# ATmega324PB device description
Architecture: AVR8; Family: megaAVR
Registers are 8-bit, access not given, no defined reset value unless marked. A register's access mark holds for its fields unless they carry their own. Offsets are from the block's base; [hi:lo] are bit positions.

## EEPROM
Instances: EEPROM 0x00
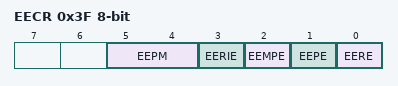
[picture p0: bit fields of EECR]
0x3F EECR — EEPROM Control Register
  [5:4] EEPM — EEPROM Programming Mode Bits
    0=Erase and Write in one operation; 1=Erase Only; 2=Write Only
  [3] EERIE — EEPROM Ready Interrupt Enable
  [2] EEMPE — EEPROM Master Programming Enable
  [1] EEPE — EEPROM Programming Enable
  [0] EERE — EEPROM Read Enable
0x40 EEDR — EEPROM Data Register
0x41 EEAR 16-bit bits used 11:0 — EEPROM Address Register Low Bytes

## SPI0 — Serial Peripheral Interface
Instances: SPI0 0x00
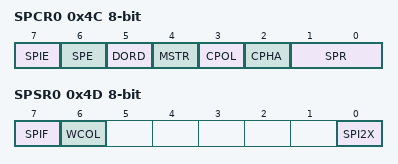
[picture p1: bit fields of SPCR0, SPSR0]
0x4C SPCR0 — SPI Control Register
  [7] SPIE — SPI Interrupt Enable
  [6] SPE — SPI Enable
  [5] DORD — Data Order
  [4] MSTR — Master/Slave Select
  [3] CPOL — Clock polarity
  [2] CPHA — Clock Phase
  [1:0] SPR — SPI Clock Rate Select
    0=fosc/4; 1=fosc/16; 2=fosc/64; 3=fosc/128; 4=fosc/2; 5=fosc/8; 6=fosc/32; 7=fosc/64
0x4D SPSR0 — SPI Status Register
  [7] SPIF — SPI Interrupt Flag
  [6] WCOL — Write Collision Flag
  [0] SPI2X — Double SPI Speed Bit
0x4E SPDR0 — SPI Data Register

## SPI1 — Serial Peripheral Interface
Instances: SPI1 0x00
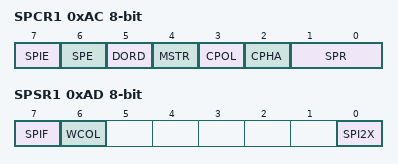
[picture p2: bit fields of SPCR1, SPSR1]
0xAC SPCR1 — SPI Control Register
  [7] SPIE — SPI Interrupt Enable
  [6] SPE — SPI Enable
  [5] DORD — Data Order
  [4] MSTR — Master/Slave Select
  [3] CPOL — Clock polarity
  [2] CPHA — Clock Phase
  [1:0] SPR — SPI Clock Rate Select
    0=fosc/4; 1=fosc/16; 2=fosc/64; 3=fosc/128; 4=fosc/2; 5=fosc/8; 6=fosc/32; 7=fosc/64
0xAD SPSR1 — SPI Status Register
  [7] SPIF — SPI Interrupt Flag
  [6] WCOL — Write Collision Flag
  [0] SPI2X — Double SPI Speed Bit
0xAE SPDR1 — SPI Data Register

## TWI0 — Two Wire Serial Interface
Instances: TWI0 0x00
0xB8 TWBR0 — TWI Bit Rate register
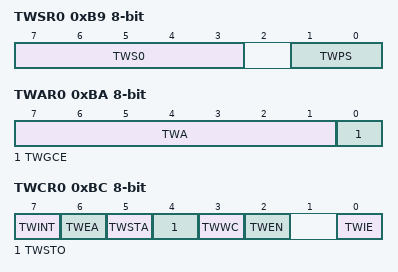
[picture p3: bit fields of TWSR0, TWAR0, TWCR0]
0xB9 TWSR0 — TWI Status Register
  [7:3] TWS0 (bit 3 of the value upward) — TWI Status
  [1:0] TWPS — TWI Prescaler
    0=1; 1=4; 2=16; 3=64
0xBA TWAR0 — TWI (Slave) Address register
  [7:1] TWA — TWI (Slave) Address register Bits
  [0] TWGCE — TWI General Call Recognition Enable Bit
0xBB TWDR0 — TWI Data register
0xBC TWCR0 — TWI Control Register
  [7] TWINT — TWI Interrupt Flag
  [6] TWEA — TWI Enable Acknowledge Bit
  [5] TWSTA — TWI Start Condition Bit
  [4] TWSTO — TWI Stop Condition Bit
  [3] TWWC — TWI Write Collition Flag
  [2] TWEN — TWI Enable Bit
  [0] TWIE — TWI Interrupt Enable
0xBD TWAMR0 — TWI (Slave) Address Mask Register
  [7:1] TWAM0

## TWI1 — Two Wire Serial Interface
Instances: TWI1 0x00
0xD8 TWBR1 — TWI Bit Rate register
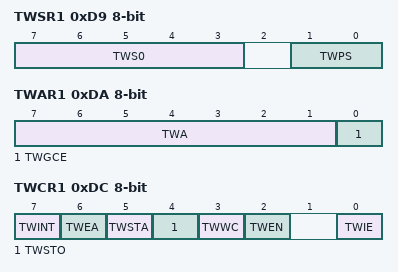
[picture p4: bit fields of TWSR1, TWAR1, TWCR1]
0xD9 TWSR1 — TWI Status Register
  [7:3] TWS0 (bit 3 of the value upward) — TWI Status
  [1:0] TWPS — TWI Prescaler
    0=1; 1=4; 2=16; 3=64
0xDA TWAR1 — TWI (Slave) Address register
  [7:1] TWA — TWI (Slave) Address register Bits
  [0] TWGCE — TWI General Call Recognition Enable Bit
0xDB TWDR1 — TWI Data register
0xDC TWCR1 — TWI Control Register
  [7] TWINT — TWI Interrupt Flag
  [6] TWEA — TWI Enable Acknowledge Bit
  [5] TWSTA — TWI Start Condition Bit
  [4] TWSTO — TWI Stop Condition Bit
  [3] TWWC — TWI Write Collition Flag
  [2] TWEN — TWI Enable Bit
  [0] TWIE — TWI Interrupt Enable
0xDD TWAMR1 — TWI (Slave) Address Mask Register
  [7:1] TWAM1

## CFD — Clock Failure Detection
Instances: CFD 0x00
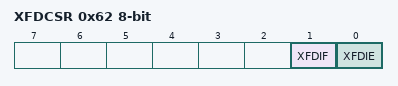
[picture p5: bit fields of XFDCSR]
0x62 XFDCSR — XOSC Failure Detection Control and Status Register
  [1] XFDIF — Failure Detection Interrupt Flag
  [0] XFDIE — Failure Detection Interrupt Enable

## CPU — CPU Registers
Instances: CPU 0x00
Parameters: CORE_VERSION=V2E
0x3E GPIOR0 — General Purpose IO Register 0
0x4A GPIOR1 — General Purpose IO Register 1
0x4B GPIOR2 — General Purpose IO Register 2
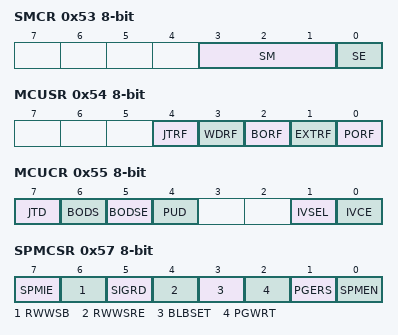
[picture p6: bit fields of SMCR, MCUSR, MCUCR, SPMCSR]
0x53 SMCR — Sleep Mode Control Register
  [3:1] SM — Sleep Mode Select bits
    0=IDLE; 1=ADC (ADC Noise Reduction (If Available)); 2=PDOWN (Power Down); 3=PSAVE (Power Save); 6=STDBY (Standby); 7=ESTDBY (Extended Standby)
  [0] SE — Sleep Enable
0x54 MCUSR — MCU Status Register
  [4] JTRF — JTAG Reset Flag
  [3] WDRF — Watchdog Reset Flag
  [2] BORF — Brown-out Reset Flag
  [1] EXTRF — External Reset Flag
  [0] PORF — Power-on reset flag
0x55 MCUCR — MCU Control Register
  [7] JTD — JTAG Interface Disable
  [6] BODS — BOD Power Down in Sleep
  [5] BODSE — BOD Power Down in Sleep Enable
  [4] PUD — Pull-up disable
  [1] IVSEL — Interrupt Vector Select
  [0] IVCE — Interrupt Vector Change Enable
0x57 SPMCSR — Store Program Memory Control Register
  [7] SPMIE — SPM Interrupt Enable
  [6] RWWSB — Read While Write Section Busy
  [5] SIGRD — Signature Row Read
  [4] RWWSRE — Read While Write section read enable
  [3] BLBSET — Boot Lock Bit Set
  [2] PGWRT — Page Write
  [1] PGERS — Page Erase
  [0] SPMEN — Store Program Memory Enable
0x5D SP 16-bit bits used 12:0 — Stack Pointer
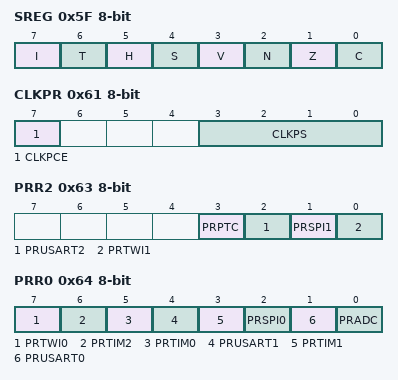
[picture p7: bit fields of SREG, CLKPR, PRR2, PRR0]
0x5F SREG — Status Register
  [7] I — Global Interrupt Enable
  [6] T — Bit Copy Storage
  [5] H — Half Carry Flag
  [4] S — Sign Bit
  [3] V — Two's Complement Overflow Flag
  [2] N — Negative Flag
  [1] Z — Zero Flag
  [0] C — Carry Flag
0x61 CLKPR
  [7] CLKPCE
  [3:0] CLKPS
    0=1; 1=2; 2=4; 3=8; 4=16; 5=32; 6=64; 7=128; 8=256
0x63 PRR2 — Power Reduction Register2
  [3] PRPTC — Power Reduction Peripheral Touch Controller
  [2] PRUSART2 — Power Reduction USART2
  [1] PRSPI1 — Power Reduction Serial Peripheral Interface 1
  [0] PRTWI1 — Power Reduction TWI1
0x64 PRR0 — Power Reduction Register0
  [7] PRTWI0 — Power Reduction TWI0
  [6] PRTIM2 — Power Reduction Timer/Counter2
  [5] PRTIM0 — Power Reduction Timer/Counter0
  [4] PRUSART1 — Power Reduction USART1
  [3] PRTIM1 — Power Reduction Timer/Counter1
  [2] PRSPI0 — Power Reduction Serial Peripheral Interface 0
  [1] PRUSART0 — Power Reduction USART0
  [0] PRADC — Power Reduction ADC
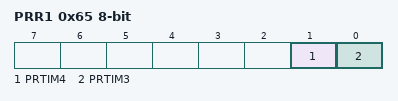
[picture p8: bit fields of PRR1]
0x65 PRR1 — Power Reduction Register1
  [1] PRTIM4 — Power Reduction Timer/Counter4
  [0] PRTIM3 — Power Reduction Timer/Counter3
0x66 OSCCAL — Oscillator Calibration Value
  [7:0] OSCCAL — Oscillator Calibration
Value list OSCCAL_VALUE_ADDRESSES: 0=8_0_MHz
